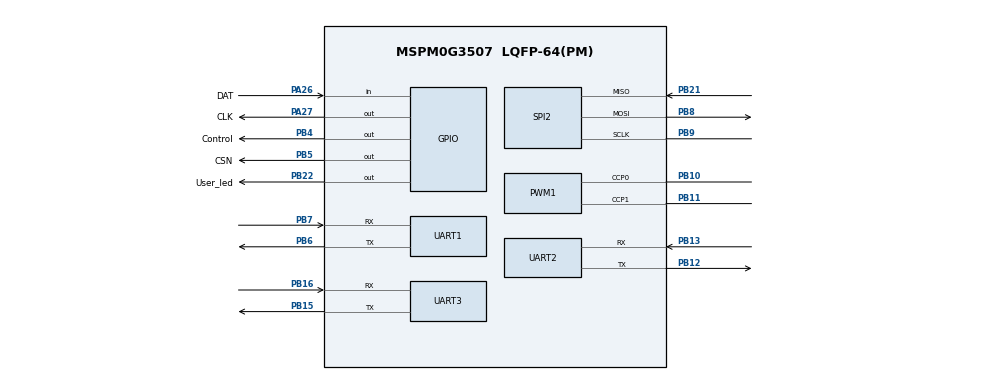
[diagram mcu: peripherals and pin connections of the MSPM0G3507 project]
/**
 * AI AGENTS: Do not edit this file directly. There is no validation or error feedback when
 * editing manually — mistakes will be silent until the file is loaded in SysConfig.
 * Use the SysConfig MCP server instead to make changes with immediate error reporting.
 *
 * These arguments were used when this file was generated. They will be automatically applied on subsequent loads
 * via the GUI or CLI. Run CLI with '--help' for additional information on how to override these arguments.
 * @cliArgs --device "MSPM0G350X" --part "Default" --package "LQFP-64(PM)" --product "mspm0_sdk@2.10.00.04"
 * @v2CliArgs --device "MSPM0G3507" --package "LQFP-64(PM)" --product "mspm0_sdk@2.10.00.04"
 * @versions {"tool":"1.28.0+4712"}
 */

/**
 * Import the modules used in this configuration.
 */
const ADC12         = scripting.addModule("/ti/driverlib/ADC12", {}, false);
const ADC121        = ADC12.addInstance();
const GPIO          = scripting.addModule("/ti/driverlib/GPIO", {}, false);
const GPIO1         = GPIO.addInstance();
const GPIO2         = GPIO.addInstance();
const GPIO3         = GPIO.addInstance();
const GPIO4         = GPIO.addInstance();
const GPIO5         = GPIO.addInstance();
const GPIO6         = GPIO.addInstance();
const GPIO7         = GPIO.addInstance();
const GPIO8         = GPIO.addInstance();
const GPIO9         = GPIO.addInstance();
const GPIO10        = GPIO.addInstance();
const GPIO11        = GPIO.addInstance();
const I2C           = scripting.addModule("/ti/driverlib/I2C", {}, false);
const I2C1          = I2C.addInstance();
const MCAN          = scripting.addModule("/ti/driverlib/MCAN", {}, false);
const MCAN1         = MCAN.addInstance();
const PWM           = scripting.addModule("/ti/driverlib/PWM", {}, false);
const PWM1          = PWM.addInstance();
const SPI           = scripting.addModule("/ti/driverlib/SPI", {}, false);
const SPI1          = SPI.addInstance();
const SPI2          = SPI.addInstance();
const SYSCTL        = scripting.addModule("/ti/driverlib/SYSCTL");
const TIMER         = scripting.addModule("/ti/driverlib/TIMER", {}, false);
const TIMER1        = TIMER.addInstance();
const TIMER2        = TIMER.addInstance();
const TIMER3        = TIMER.addInstance();
const UART          = scripting.addModule("/ti/driverlib/UART", {}, false);
const UART1         = UART.addInstance();
const UART2         = UART.addInstance();
const UART3         = UART.addInstance();
const ProjectConfig = scripting.addModule("/ti/project_config/ProjectConfig");

/**
 * Write custom configuration values to the imported modules.
 */
const divider9       = system.clockTree["UDIV"];
divider9.divideValue = 2;

const gate7  = system.clockTree["MFCLKGATE"];
gate7.enable = true;

const multiplier2         = system.clockTree["PLL_QDIV"];
multiplier2.multiplyValue = 4;

const mux4       = system.clockTree["EXHFMUX"];
mux4.inputSelect = "EXHFMUX_XTAL";

const mux8       = system.clockTree["HSCLKMUX"];
mux8.inputSelect = "HSCLKMUX_SYSPLL0";

const mux12       = system.clockTree["SYSPLLMUX"];
mux12.inputSelect = "zSYSPLLMUX_HFCLK";

const pinFunction4        = system.clockTree["HFXT"];
pinFunction4.inputFreq    = 40;
pinFunction4.enable       = true;
pinFunction4.HFXTStartup  = 10;
pinFunction4.HFCLKMonitor = true;

ADC121.sampClkDiv                 = "DL_ADC12_CLOCK_DIVIDE_8";
ADC121.$name                      = "ADC1";
ADC121.adcMem0_name               = "ADC_Channel8";
ADC121.adcMem0chansel             = "DL_ADC12_INPUT_CHAN_8";
ADC121.powerDownMode              = "DL_ADC12_POWER_DOWN_MODE_MANUAL";
ADC121.repeatMode                 = true;
ADC121.adcMem8chansel             = "DL_ADC12_INPUT_CHAN_8";
ADC121.adcMem8_name               = "Channel8";
ADC121.enabledInterrupts          = ["DL_ADC12_INTERRUPT_MEM0_RESULT_LOADED"];
ADC121.sampleTime0                = "0.01 ms";
ADC121.peripheral.$assign         = "ADC1";
ADC121.peripheral.adcPin8.$assign = "PA22";
ADC121.adcPin8Config.$name        = "ti_driverlib_gpio_GPIOPinGeneric4";

const Board = scripting.addModule("/ti/driverlib/Board", {}, false);

GPIO1.$name                              = "BEEP";
GPIO1.port                               = "PORTA";
GPIO1.associatedPins[0].$name            = "PIN_14";
GPIO1.associatedPins[0].assignedPin      = "14";
GPIO1.associatedPins[0].internalResistor = "PULL_UP";

GPIO2.$name                              = "KEY";
GPIO2.associatedPins.create(4);
GPIO2.associatedPins[0].$name            = "key1";
GPIO2.associatedPins[0].direction        = "INPUT";
GPIO2.associatedPins[0].assignedPort     = "PORTA";
GPIO2.associatedPins[0].assignedPin      = "30";
GPIO2.associatedPins[0].internalResistor = "PULL_UP";
GPIO2.associatedPins[1].$name            = "key2";
GPIO2.associatedPins[1].direction        = "INPUT";
GPIO2.associatedPins[1].assignedPort     = "PORTA";
GPIO2.associatedPins[1].assignedPin      = "31";
GPIO2.associatedPins[1].internalResistor = "PULL_UP";
GPIO2.associatedPins[2].$name            = "key3";
GPIO2.associatedPins[2].assignedPort     = "PORTB";
GPIO2.associatedPins[2].assignedPin      = "0";
GPIO2.associatedPins[2].direction        = "INPUT";
GPIO2.associatedPins[2].internalResistor = "PULL_UP";
GPIO2.associatedPins[3].$name            = "key4";
GPIO2.associatedPins[3].assignedPort     = "PORTB";
GPIO2.associatedPins[3].assignedPin      = "1";
GPIO2.associatedPins[3].direction        = "INPUT";
GPIO2.associatedPins[3].internalResistor = "PULL_UP";

GPIO3.$name                          = "Motor_dir";
GPIO3.associatedPins.create(4);
GPIO3.associatedPins[0].assignedPort = "PORTA";
GPIO3.associatedPins[0].assignedPin  = "7";
GPIO3.associatedPins[0].$name        = "EN1_A";
GPIO3.associatedPins[1].$name        = "EN1_B";
GPIO3.associatedPins[1].assignedPort = "PORTA";
GPIO3.associatedPins[1].assignedPin  = "21";
GPIO3.associatedPins[2].assignedPort = "PORTA";
GPIO3.associatedPins[2].assignedPin  = "18";
GPIO3.associatedPins[2].$name        = "EN2_A";
GPIO3.associatedPins[3].assignedPort = "PORTB";
GPIO3.associatedPins[3].assignedPin  = "14";
GPIO3.associatedPins[3].$name        = "EN2_B";

GPIO4.$name                               = "ENCODER";
GPIO4.associatedPins.create(4);
GPIO4.associatedPins[0].direction         = "INPUT";
GPIO4.associatedPins[0].assignedPort      = "PORTB";
GPIO4.associatedPins[0].assignedPin       = "2";
GPIO4.associatedPins[0].interruptEn       = true;
GPIO4.associatedPins[0].polarity          = "RISE";
GPIO4.associatedPins[0].interruptPriority = "3";
GPIO4.associatedPins[0].$name             = "ENC_A2";
GPIO4.associatedPins[1].direction         = "INPUT";
GPIO4.associatedPins[1].assignedPort      = "PORTB";
GPIO4.associatedPins[1].assignedPin       = "3";
GPIO4.associatedPins[1].interruptEn       = true;
GPIO4.associatedPins[1].polarity          = "RISE";
GPIO4.associatedPins[1].interruptPriority = "3";
GPIO4.associatedPins[1].$name             = "ENC_B2";
GPIO4.associatedPins[2].direction         = "INPUT";
GPIO4.associatedPins[2].interruptEn       = true;
GPIO4.associatedPins[2].polarity          = "RISE";
GPIO4.associatedPins[2].interruptPriority = "3";
GPIO4.associatedPins[2].assignedPort      = "PORTB";
GPIO4.associatedPins[2].assignedPin       = "18";
GPIO4.associatedPins[2].$name             = "ENC_A1";
GPIO4.associatedPins[3].direction         = "INPUT";
GPIO4.associatedPins[3].assignedPort      = "PORTB";
GPIO4.associatedPins[3].assignedPin       = "19";
GPIO4.associatedPins[3].interruptEn       = true;
GPIO4.associatedPins[3].polarity          = "RISE";
GPIO4.associatedPins[3].interruptPriority = "3";
GPIO4.associatedPins[3].$name             = "ENC_B1";

GPIO5.$name                          = "ICM42688_CS";
GPIO5.associatedPins[0].$name        = "CS";
GPIO5.associatedPins[0].assignedPort = "PORTA";
GPIO5.associatedPins[0].assignedPin  = "29";

GPIO6.$name                              = "ZDT_Motor";
GPIO6.associatedPins.create(4);
GPIO6.associatedPins[0].$name            = "Yaw_Dir";
GPIO6.associatedPins[0].assignedPort     = "PORTA";
GPIO6.associatedPins[0].internalResistor = "PULL_DOWN";
GPIO6.associatedPins[0].assignedPin      = "15";
GPIO6.associatedPins[1].assignedPort     = "PORTA";
GPIO6.associatedPins[1].internalResistor = "PULL_DOWN";
GPIO6.associatedPins[1].$name            = "Pitch_Dir";
GPIO6.associatedPins[1].assignedPin      = "8";
GPIO6.associatedPins[2].$name            = "Yaw_Stp";
GPIO6.associatedPins[2].internalResistor = "PULL_DOWN";
GPIO6.associatedPins[2].assignedPort     = "PORTA";
GPIO6.associatedPins[2].assignedPin      = "17";
GPIO6.associatedPins[3].$name            = "Pitch_Stp";
GPIO6.associatedPins[3].internalResistor = "PULL_DOWN";
GPIO6.associatedPins[3].assignedPort     = "PORTA";
GPIO6.associatedPins[3].assignedPin      = "9";

GPIO7.$name                              = "RELAY";
GPIO7.associatedPins[0].$name            = "Control";
GPIO7.associatedPins[0].internalResistor = "PULL_UP";
GPIO7.associatedPins[0].pin.$assign      = "PB4";

GPIO8.$name                          = "Gray_Address";
GPIO8.associatedPins.create(3);
GPIO8.associatedPins[0].$name        = "PIN_0";
GPIO8.associatedPins[0].assignedPort = "PORTA";
GPIO8.associatedPins[0].assignedPin  = "24";
GPIO8.associatedPins[1].$name        = "PIN_1";
GPIO8.associatedPins[1].assignedPort = "PORTB";
GPIO8.associatedPins[1].assignedPin  = "25";
GPIO8.associatedPins[2].$name        = "PIN_2";
GPIO8.associatedPins[2].assignedPin  = "24";
GPIO8.associatedPins[2].assignedPort = "PORTB";

GPIO9.$name                         = "User_LED";
GPIO9.port                          = "PORTB";
GPIO9.associatedPins[0].$name       = "User_led";
GPIO9.associatedPins[0].pin.$assign = "PB22";

GPIO10.$name                         = "Gray_Serial";
GPIO10.associatedPins.create(2);
GPIO10.associatedPins[0].$name       = "DAT";
GPIO10.associatedPins[0].direction   = "INPUT";
GPIO10.associatedPins[0].pin.$assign = "PA26";
GPIO10.associatedPins[1].$name       = "CLK";
GPIO10.associatedPins[1].pin.$assign = "PA27";

GPIO11.$name                          = "NRF24L";
GPIO11.port                           = "PORTB";
GPIO11.associatedPins.create(2);
GPIO11.associatedPins[0].$name        = "CSN";
GPIO11.associatedPins[0].initialValue = "SET";
GPIO11.associatedPins[0].pin.$assign  = "PB5";
GPIO11.associatedPins[1].$name        = "CE";

I2C1.$name                     = "I2C_0";
I2C1.advDigitalGlitchFilter    = "CLOCKS_1";
I2C1.advControllerRXFIFOTRIG   = "BYTES_8";
I2C1.advControllerTXFIFOTRIG   = "BYTES_7";
I2C1.enableDMAEvent1           = false;
I2C1.enableDMAEvent2           = false;
I2C1.basicEnableController     = true;
I2C1.peripheral.$assign        = "I2C0";
I2C1.sdaPinConfig.$name        = "ti_driverlib_gpio_GPIOPinGeneric13";
I2C1.sdaPinConfig.enableConfig = true;
I2C1.sclPinConfig.$name        = "ti_driverlib_gpio_GPIOPinGeneric14";
I2C1.sclPinConfig.enableConfig = true;

MCAN1.$name                = "MCAN0";
MCAN1.fdMode               = false;
MCAN1.wkupReqEnable        = true;
MCAN1.autoWkupEnable       = true;
MCAN1.emulationEnable      = true;
MCAN1.spPercent            = 80;
MCAN1.desiredNomRate       = 1000;
MCAN1.enableInterrupt      = true;
MCAN1.overrideRetention    = true;
MCAN1.interruptFlags       = ["DL_MCAN_INTERRUPT_RF0N"];
MCAN1.interruptLine        = ["DL_MCAN_INTR_LINE_NUM_1"];
MCAN1.interruptLine1Flag   = ["DL_MCAN_INTR_MASK_ALL"];
MCAN1.m0interrupts         = ["DL_MCAN_MSP_INTERRUPT_LINE1"];
MCAN1.additionalCoreConfig = true;
MCAN1.rrfe                 = true;
MCAN1.rrfs                 = true;
MCAN1.txPinConfig.$name    = "ti_driverlib_gpio_GPIOPinGeneric7";
MCAN1.rxPinConfig.$name    = "ti_driverlib_gpio_GPIOPinGeneric10";

PWM1.$name                              = "Motor";
PWM1.timerStartTimer                    = true;
PWM1.timerCount                         = 2500;
PWM1.peripheral.$assign                 = "TIMG0";
PWM1.peripheral.ccp0Pin.$assign         = "PB10";
PWM1.peripheral.ccp1Pin.$assign         = "PB11";
PWM1.PWM_CHANNEL_0.$name                = "ti_driverlib_pwm_PWMTimerCC2";
PWM1.PWM_CHANNEL_0.invert               = true;
PWM1.PWM_CHANNEL_1.$name                = "ti_driverlib_pwm_PWMTimerCC3";
PWM1.PWM_CHANNEL_1.invert               = true;
PWM1.ccp0PinConfig.$name                = "ti_driverlib_gpio_GPIOPinGeneric5";
PWM1.ccp0PinConfig.direction            = scripting.forceWrite("OUTPUT");
PWM1.ccp0PinConfig.hideOutputInversion  = scripting.forceWrite(false);
PWM1.ccp0PinConfig.onlyInternalResistor = scripting.forceWrite(false);
PWM1.ccp0PinConfig.passedPeripheralType = scripting.forceWrite("Digital");
PWM1.ccp1PinConfig.$name                = "ti_driverlib_gpio_GPIOPinGeneric6";
PWM1.ccp1PinConfig.direction            = scripting.forceWrite("OUTPUT");
PWM1.ccp1PinConfig.hideOutputInversion  = scripting.forceWrite(false);
PWM1.ccp1PinConfig.onlyInternalResistor = scripting.forceWrite(false);
PWM1.ccp1PinConfig.passedPeripheralType = scripting.forceWrite("Digital");

SPI1.$name                              = "ICM42688";
SPI1.polarity                           = "1";
SPI1.phase                              = "1";
SPI1.frameFormat                        = "MOTO3";
SPI1.sclkPinConfig.direction            = scripting.forceWrite("OUTPUT");
SPI1.sclkPinConfig.onlyInternalResistor = scripting.forceWrite(false);
SPI1.sclkPinConfig.passedPeripheralType = scripting.forceWrite("Digital");
SPI1.sclkPinConfig.$name                = "ti_driverlib_gpio_GPIOPinGeneric2";
SPI1.mosiPinConfig.direction            = scripting.forceWrite("OUTPUT");
SPI1.mosiPinConfig.hideOutputInversion  = scripting.forceWrite(false);
SPI1.mosiPinConfig.onlyInternalResistor = scripting.forceWrite(false);
SPI1.mosiPinConfig.passedPeripheralType = scripting.forceWrite("Digital");
SPI1.mosiPinConfig.$name                = "ti_driverlib_gpio_GPIOPinGeneric3";
SPI1.misoPinConfig.onlyInternalResistor = scripting.forceWrite(false);
SPI1.misoPinConfig.passedPeripheralType = scripting.forceWrite("Digital");
SPI1.misoPinConfig.$name                = "ti_driverlib_gpio_GPIOPinGeneric8";
SPI1.peripheral.$assign                 = "SPI0";

SPI2.$name                              = "NRF24L01";
SPI2.frameFormat                        = "MOTO3";
SPI2.sclkPinConfig.$name                = "ti_driverlib_gpio_GPIOPinGeneric9";
SPI2.sclkPinConfig.direction            = scripting.forceWrite("OUTPUT");
SPI2.sclkPinConfig.onlyInternalResistor = scripting.forceWrite(false);
SPI2.sclkPinConfig.passedPeripheralType = scripting.forceWrite("Digital");
SPI2.mosiPinConfig.$name                = "ti_driverlib_gpio_GPIOPinGeneric17";
SPI2.mosiPinConfig.direction            = scripting.forceWrite("OUTPUT");
SPI2.mosiPinConfig.hideOutputInversion  = scripting.forceWrite(false);
SPI2.mosiPinConfig.onlyInternalResistor = scripting.forceWrite(false);
SPI2.mosiPinConfig.passedPeripheralType = scripting.forceWrite("Digital");
SPI2.misoPinConfig.$name                = "ti_driverlib_gpio_GPIOPinGeneric18";
SPI2.misoPinConfig.onlyInternalResistor = scripting.forceWrite(false);
SPI2.misoPinConfig.passedPeripheralType = scripting.forceWrite("Digital");
SPI2.peripheral.$assign                 = "SPI1";
SPI2.peripheral.sclkPin.$assign         = "PB9";
SPI2.peripheral.mosiPin.$assign         = "PB8";
SPI2.peripheral.misoPin.$assign         = "PB21";

SYSCTL.clockTreeEn = true;

TIMER1.$name              = "TIMER_TICK";
TIMER1.timerClkDiv        = 8;
TIMER1.timerClkPrescale   = 10;
TIMER1.timerMode          = "PERIODIC";
TIMER1.timerStartTimer    = true;
TIMER1.interrupts         = ["ZERO"];
TIMER1.interruptPriority  = "3";
TIMER1.timerPeriod        = "10 ms";
TIMER1.peripheral.$assign = "TIMA0";

TIMER2.$name              = "dwt";
TIMER2.timerStartTimer    = true;
TIMER2.timerMode          = "PERIODIC_UP";
TIMER2.timerPeriod        = "53687ms";
TIMER2.peripheral.$assign = "TIMG12";

TIMER3.$name              = "ZDT_MOTOR_TICK";
TIMER3.timerClkPrescale   = 10;
TIMER3.timerMode          = "PERIODIC";
TIMER3.timerPeriod        = "0.3 ms";
TIMER3.timerStartTimer    = true;
TIMER3.interrupts         = ["ZERO"];
TIMER3.peripheral.$assign = "TIMG6";

UART1.enabledInterrupts                = ["RX"];
UART1.$name                            = "UART_1";
UART1.targetBaudRate                   = 115200;
UART1.peripheral.$assign               = "UART1";
UART1.peripheral.rxPin.$assign         = "PB7";
UART1.peripheral.txPin.$assign         = "PB6";
UART1.txPinConfig.direction            = scripting.forceWrite("OUTPUT");
UART1.txPinConfig.hideOutputInversion  = scripting.forceWrite(false);
UART1.txPinConfig.onlyInternalResistor = scripting.forceWrite(false);
UART1.txPinConfig.passedPeripheralType = scripting.forceWrite("Digital");
UART1.txPinConfig.$name                = "ti_driverlib_gpio_GPIOPinGeneric0";
UART1.rxPinConfig.hideOutputInversion  = scripting.forceWrite(false);
UART1.rxPinConfig.onlyInternalResistor = scripting.forceWrite(false);
UART1.rxPinConfig.passedPeripheralType = scripting.forceWrite("Digital");
UART1.rxPinConfig.$name                = "ti_driverlib_gpio_GPIOPinGeneric1";

UART2.$name                            = "UART_0";
UART2.enabledInterrupts                = ["RX"];
UART2.targetBaudRate                   = 115200;
UART2.peripheral.rxPin.$assign         = "PB13";
UART2.peripheral.txPin.$assign         = "PB12";
UART2.txPinConfig.direction            = scripting.forceWrite("OUTPUT");
UART2.txPinConfig.hideOutputInversion  = scripting.forceWrite(false);
UART2.txPinConfig.onlyInternalResistor = scripting.forceWrite(false);
UART2.txPinConfig.passedPeripheralType = scripting.forceWrite("Digital");
UART2.txPinConfig.$name                = "ti_driverlib_gpio_GPIOPinGeneric11";
UART2.rxPinConfig.hideOutputInversion  = scripting.forceWrite(false);
UART2.rxPinConfig.onlyInternalResistor = scripting.forceWrite(false);
UART2.rxPinConfig.passedPeripheralType = scripting.forceWrite("Digital");
UART2.rxPinConfig.$name                = "ti_driverlib_gpio_GPIOPinGeneric12";

UART3.$name                            = "K230";
UART3.enabledInterrupts                = ["RX"];
UART3.targetBaudRate                   = 115200;
UART3.peripheral.$assign               = "UART2";
UART3.peripheral.rxPin.$assign         = "PB16";
UART3.peripheral.txPin.$assign         = "PB15";
UART3.txPinConfig.direction            = scripting.forceWrite("OUTPUT");
UART3.txPinConfig.hideOutputInversion  = scripting.forceWrite(false);
UART3.txPinConfig.onlyInternalResistor = scripting.forceWrite(false);
UART3.txPinConfig.passedPeripheralType = scripting.forceWrite("Digital");
UART3.txPinConfig.$name                = "ti_driverlib_gpio_GPIOPinGeneric15";
UART3.rxPinConfig.hideOutputInversion  = scripting.forceWrite(false);
UART3.rxPinConfig.onlyInternalResistor = scripting.forceWrite(false);
UART3.rxPinConfig.passedPeripheralType = scripting.forceWrite("Digital");
UART3.rxPinConfig.$name                = "ti_driverlib_gpio_GPIOPinGeneric16";

ProjectConfig.genDisable      = true;
ProjectConfig.switchCondition = true;
scripting.suppress("Project Configuration File generation is disabled for this project\\. SysConfig Project Migration is not currently supported for this project\\.", ProjectConfig);

/**
 * Pinmux solution for unlocked pins/peripherals. This ensures that minor changes to the automatic solver in a future
 * version of the tool will not impact the pinmux you originally saw.  These lines can be completely deleted in order to
 * re-solve from scratch.
 */
pinFunction4.peripheral.$suggestSolution           = "SYSCTL";
pinFunction4.peripheral.hfxInPin.$suggestSolution  = "PA5";
pinFunction4.peripheral.hfxOutPin.$suggestSolution = "PA6";
Board.peripheral.$suggestSolution                  = "DEBUGSS";
Board.peripheral.swclkPin.$suggestSolution         = "PA20";
Board.peripheral.swdioPin.$suggestSolution         = "PA19";
GPIO1.associatedPins[0].pin.$suggestSolution       = "PA14";
GPIO2.associatedPins[0].pin.$suggestSolution       = "PA30";
GPIO2.associatedPins[1].pin.$suggestSolution       = "PA31";
GPIO2.associatedPins[2].pin.$suggestSolution       = "PB0";
GPIO2.associatedPins[3].pin.$suggestSolution       = "PB1";
GPIO3.associatedPins[0].pin.$suggestSolution       = "PA7";
GPIO3.associatedPins[1].pin.$suggestSolution       = "PA21";
GPIO3.associatedPins[2].pin.$suggestSolution       = "PA18";
GPIO3.associatedPins[3].pin.$suggestSolution       = "PB14";
GPIO4.associatedPins[0].pin.$suggestSolution       = "PB2";
GPIO4.associatedPins[1].pin.$suggestSolution       = "PB3";
GPIO4.associatedPins[2].pin.$suggestSolution       = "PB18";
GPIO4.associatedPins[3].pin.$suggestSolution       = "PB19";
GPIO5.associatedPins[0].pin.$suggestSolution       = "PA29";
GPIO6.associatedPins[0].pin.$suggestSolution       = "PA15";
GPIO6.associatedPins[1].pin.$suggestSolution       = "PA8";
GPIO6.associatedPins[2].pin.$suggestSolution       = "PA17";
GPIO6.associatedPins[3].pin.$suggestSolution       = "PA9";
GPIO8.associatedPins[0].pin.$suggestSolution       = "PA24";
GPIO8.associatedPins[1].pin.$suggestSolution       = "PB25";
GPIO8.associatedPins[2].pin.$suggestSolution       = "PB24";
GPIO11.associatedPins[1].pin.$suggestSolution      = "PB20";
I2C1.peripheral.sdaPin.$suggestSolution            = "PA0";
I2C1.peripheral.sclPin.$suggestSolution            = "PA1";
MCAN1.peripheral.$suggestSolution                  = "CANFD0";
MCAN1.peripheral.rxPin.$suggestSolution            = "PA13";
MCAN1.peripheral.txPin.$suggestSolution            = "PA12";
SPI1.peripheral.sclkPin.$suggestSolution           = "PA11";
SPI1.peripheral.mosiPin.$suggestSolution           = "PB17";
SPI1.peripheral.misoPin.$suggestSolution           = "PA10";
UART2.peripheral.$suggestSolution                  = "UART3";
